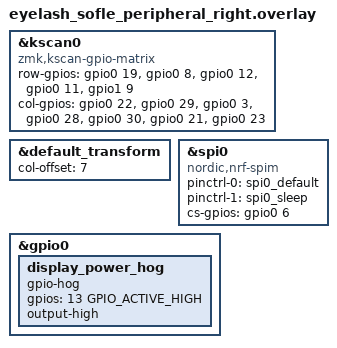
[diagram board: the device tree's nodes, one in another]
/*
*
* Copyright (c) 2021 Darryl deHaan
* SPDX-License-Identifier: MIT
*
*/

#include "eyelash_sofle.dtsi"
#include <behaviors/battery_history_request.dtsi>

&kscan0 {
    compatible = "zmk,kscan-gpio-matrix";
    row-gpios
        = <&gpio0 19 (GPIO_ACTIVE_HIGH | GPIO_PULL_DOWN)>
        , <&gpio0 8 (GPIO_ACTIVE_HIGH | GPIO_PULL_DOWN)>
        , <&gpio0 12 (GPIO_ACTIVE_HIGH | GPIO_PULL_DOWN)>
        , <&gpio0 11 (GPIO_ACTIVE_HIGH | GPIO_PULL_DOWN)>
        , <&gpio1 9 (GPIO_ACTIVE_HIGH | GPIO_PULL_DOWN)>
        ;
    col-gpios
       = <&gpio0 22 GPIO_ACTIVE_HIGH>
        , <&gpio0 29 GPIO_ACTIVE_HIGH>
        , <&gpio0 3 GPIO_ACTIVE_HIGH>
        , <&gpio0 28 GPIO_ACTIVE_HIGH>
        , <&gpio0 30 GPIO_ACTIVE_HIGH>
        , <&gpio0 21 GPIO_ACTIVE_HIGH>
        , <&gpio0 23 GPIO_ACTIVE_HIGH>
        ;
};

&default_transform {
    col-offset = <7>;
};

nice_view_spi: &spi0 {
    compatible = "nordic,nrf-spim";
    pinctrl-0 = <&spi0_default>;
    pinctrl-1 = <&spi0_sleep>;
    pinctrl-names = "default", "sleep";
    cs-gpios = <&gpio0 6 GPIO_ACTIVE_HIGH>;
};


/* La nice!view se alimenta por P0.13 (EXT_POWER). El estado de ext_power se
 * guarda en flash: si el RGB lo apago alguna vez, la pantalla arranca sin
 * alimentacion y queda gris. Se reemplaza por un gpio-hog: siempre prendida. */
/delete-node/ &{/ext-power};

&gpio0 {
    display_power_hog {
        gpio-hog;
        gpios = <13 GPIO_ACTIVE_HIGH>;
        output-high;
    };
};
